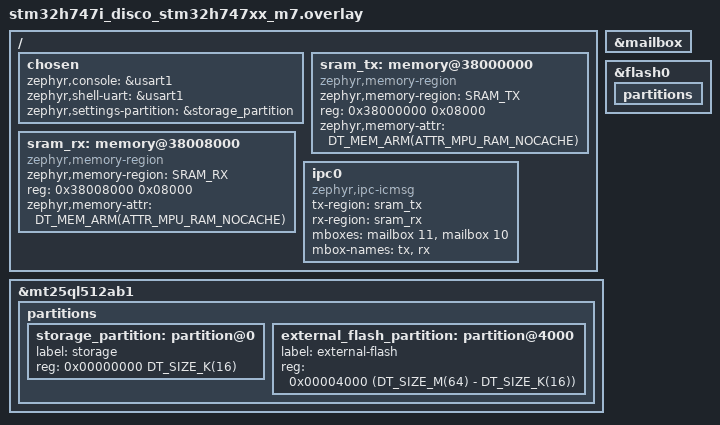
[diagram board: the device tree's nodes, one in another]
/* Phase 1: Ethernet is already enabled in the board DTS.
 * This overlay is a placeholder for future partition layout and peripheral config.
 */

/ {
	chosen {
		/delete-property/ zephyr,ipc_shm;
		zephyr,console = &usart1;
		zephyr,shell-uart = &usart1;
		zephyr,settings-partition = &storage_partition;
	};

	/delete-node/ memory@38000000;

	sram_tx: memory@38000000 {
		zephyr,memory-region = "SRAM_TX";
		compatible = "zephyr,memory-region", "mmio-sram";
		reg = <0x38000000 0x08000>;
		zephyr,memory-attr = <DT_MEM_ARM(ATTR_MPU_RAM_NOCACHE)>;
	};

	sram_rx: memory@38008000 {
		zephyr,memory-region = "SRAM_RX";
		compatible = "zephyr,memory-region", "mmio-sram";
		reg = <0x38008000 0x08000>;
		zephyr,memory-attr = <DT_MEM_ARM(ATTR_MPU_RAM_NOCACHE)>;
	};

	ipc0: ipc0 {
		compatible = "zephyr,ipc-icmsg";
		tx-region = <&sram_tx>;
		rx-region = <&sram_rx>;
		mboxes = <&mailbox 11>, <&mailbox 10>;
		mbox-names = "tx", "rx";
		status = "okay";
	};
};

&mailbox {
	status = "okay";
};

&flash0 {
	partitions {
		/delete-node/ partition@ff800;
	};
};

/* Store settings in the external QSPI NOR so the full internal flash0 remains
 * available for the M7 application image.
 */
&mt25ql512ab1 {
	partitions {
		/delete-node/ partition@0;

		storage_partition: partition@0 {
			label = "storage";
			reg = <0x00000000 DT_SIZE_K(16)>;
		};

		external_flash_partition: partition@4000 {
			label = "external-flash";
			reg = <0x00004000 (DT_SIZE_M(64) - DT_SIZE_K(16))>;
		};
	};
};
